VERSION "HIPBNYYYYYYYYYYYYYYYYYYYYYYYYYYYYYYYYYYYYY/4/%%%/4/'%**4YYY///"

NS_ :

BS_:

BU_: ACC AWD SRS EPB GW SAS ESP EMS TCU
VAL_TABLE_ SOC 1023 "Invalid value" 0 "Initial value" ;

BO_ 608 GW_260: 8 GW
 SG_ BCM_ReverseGearPosition : 8|1@0+ (1,0) [0|1] ""  ESP

BO_ 872 ESP_368: 8 ESP
 SG_ ESP_HHC_Active : 15|1@0+ (1,0) [0|1] ""  EPB

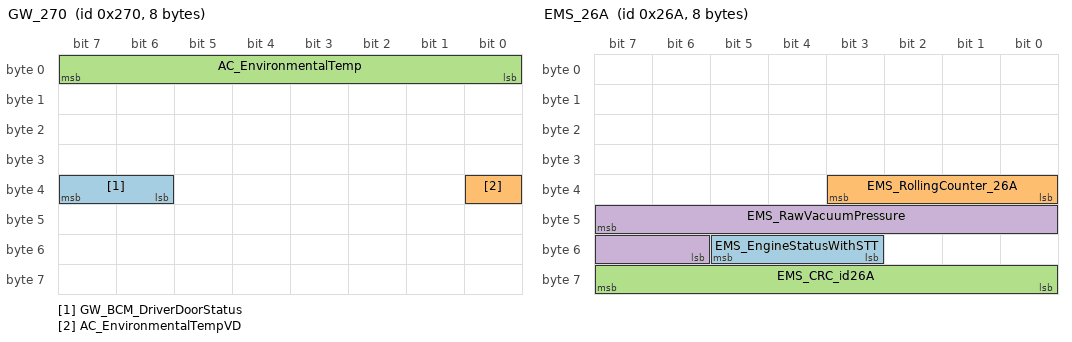
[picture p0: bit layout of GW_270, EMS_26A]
BO_ 624 GW_270: 8 GW
 SG_ GW_BCM_DriverDoorStatus : 39|2@0+ (1,0) [0|3] ""  ESP
 SG_ AC_EnvironmentalTempVD : 32|1@0+ (1,0) [0|1] ""  ESP
 SG_ AC_EnvironmentalTemp : 7|8@0+ (0.5,-40) [-40|87.5] "degree C"  ESP

BO_ 853 EMS_355: 8 EMS
 SG_ EMS_TotalOdometer : 31|24@0+ (1,0) [0|0] ""  ESP

BO_ 618 EMS_26A: 8 EMS
 SG_ EMS_EngineStatusWithSTT : 53|3@0+ (1,0) [0|7] ""  ESP
 SG_ EMS_RollingCounter_26A : 35|4@0+ (1,0) [0|15] ""  ESP
 SG_ EMS_CRC_id26A : 63|8@0+ (1,0) [0|255] ""  ESP
 SG_ EMS_RawVacuumPressure : 47|10@0+ (1.1056,-1080) [-1080|50] "mbar"  ESP

BO_ 631 ESP_277: 8 ESP
 SG_ ESP_TCSActive : 14|1@0+ (1,0) [0|1] ""  ACC
 SG_ ESP_VDCActive : 13|1@0+ (1,0) [0|1] ""  ACC
 SG_ ESP_OnlyABSActive : 15|1@0+ (1,0) [0|1] ""  ACC
 SG_ ESP_BrakeOverHeat : 24|1@0+ (1,0) [0|1] "" Vector__XXX
 SG_ ESP_ABAavailable : 20|1@0+ (1,0) [0|1] "" Vector__XXX
 SG_ ESP_CheckSum_277 : 63|8@0+ (1,0) [0|255] "" Vector__XXX
 SG_ ESP_RollingCounter_277 : 51|4@0+ (1,0) [0|15] "" Vector__XXX
 SG_ ESP_VehicleStandstill : 30|1@0+ (1,0) [0|1] "" Vector__XXX
 SG_ ESP_CDD_Available : 28|1@0+ (1,0) [0|1] "" Vector__XXX
 SG_ ESP_CDD_Active : 27|1@0+ (1,0) [0|1] "" Vector__XXX
 SG_ ESP_QDCACC : 26|2@0+ (1,0) [0|3] "" Vector__XXX
 SG_ ESP_PrefillActive : 23|1@0+ (1,0) [0|1] "" Vector__XXX
 SG_ ESP_PrefillAvailable : 22|1@0+ (1,0) [0|1] "" Vector__XXX
 SG_ ESP_ABAactive : 21|1@0+ (1,0) [0|1] ""  EMS
 SG_ ESP_AEBAvailable : 19|1@0+ (1,0) [0|1] "" Vector__XXX
 SG_ ESP_AEBdecActive : 18|1@0+ (1,0) [0|1] "" Vector__XXX
 SG_ ESP_AWBactive : 17|1@0+ (1,0) [0|1] "" Vector__XXX
 SG_ ESP_AWBavailable : 16|1@0+ (1,0) [0|1] "" Vector__XXX
 SG_ ESP_BrakeForce : 12|1@0+ (1,0) [0|1] "" Vector__XXX

BO_ 862 ACC_35E: 8 ACC
 SG_ ACC_ACCFailInfo : 23|1@0+ (1,0) [0|1] ""  ESP

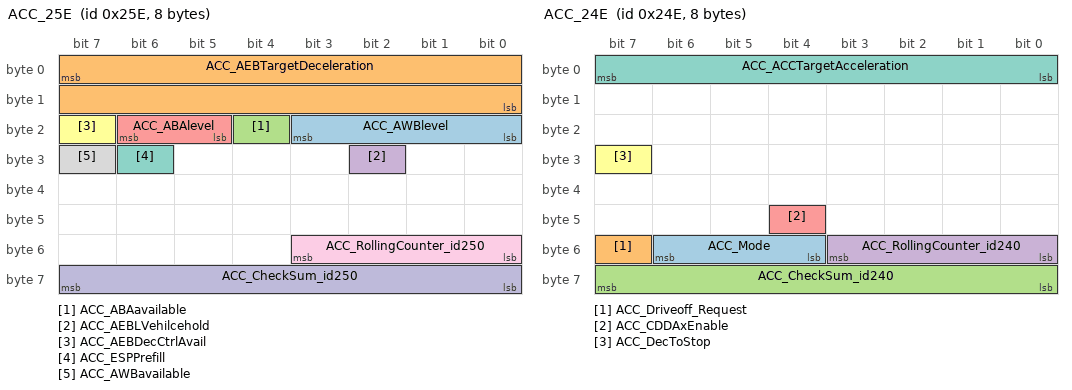
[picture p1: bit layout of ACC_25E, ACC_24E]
BO_ 606 ACC_25E: 8 ACC
 SG_ ACC_AWBlevel : 19|4@0+ (1,0) [0|15] ""  ESP
 SG_ ACC_AEBTargetDeceleration : 7|16@0+ (0.0005,-16) [-16|16] "m/s^2"  ESP
 SG_ ACC_ABAavailable : 20|1@0+ (1,0) [0|1] ""  ESP
 SG_ ACC_AEBLVehilcehold : 26|1@0+ (1,0) [0|1] ""  ESP
 SG_ ACC_ABAlevel : 22|2@0+ (1,0) [0|3] ""  ESP
 SG_ ACC_AEBDecCtrlAvail : 23|1@0+ (1,0) [0|1] ""  ESP
 SG_ ACC_ESPPrefill : 30|1@0+ (1,0) [0|1] ""  ESP
 SG_ ACC_AWBavailable : 31|1@0+ (1,0) [0|1] ""  ESP
 SG_ ACC_RollingCounter_id250 : 51|4@0+ (1,0) [0|15] ""  ESP
 SG_ ACC_CheckSum_id250 : 63|8@0+ (1,0) [0|255] ""  ESP

BO_ 590 ACC_24E: 8 ACC
 SG_ ACC_Mode : 54|3@0+ (1,0) [0|7] "" Vector__XXX
 SG_ ACC_Driveoff_Request : 55|1@0+ (1,0) [0|1] ""  ESP
 SG_ ACC_CheckSum_id240 : 63|8@0+ (1,0) [0|255] ""  ESP
 SG_ ACC_RollingCounter_id240 : 51|4@0+ (1,0) [0|15] ""  ESP
 SG_ ACC_CDDAxEnable : 44|1@0+ (1,0) [0|1] ""  ESP
 SG_ ACC_DecToStop : 31|1@0+ (1,0) [0|1] ""  ESP
 SG_ ACC_ACCTargetAcceleration : 7|8@0+ (0.05,-5) [-5|7.75] "m/s^2"  ESP

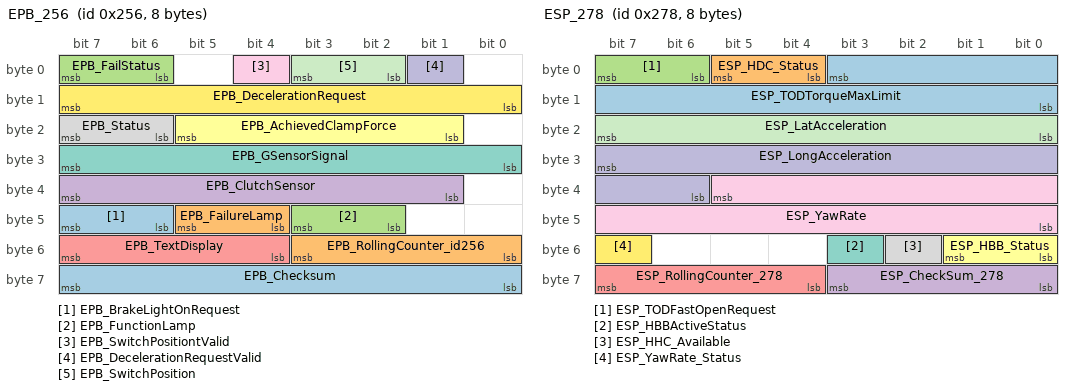
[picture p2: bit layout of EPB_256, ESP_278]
BO_ 598 EPB_256: 8 ESP
 SG_ EPB_BrakeLightOnRequest : 47|2@0+ (1,0) [0|3] ""  EPB
 SG_ EPB_FailureLamp : 45|2@0+ (1,0) [0|3] "" Vector__XXX
 SG_ EPB_FunctionLamp : 43|2@0+ (1,0) [0|3] "" Vector__XXX
 SG_ EPB_ClutchSensor : 39|7@0+ (1,0) [0|127] "" Vector__XXX
 SG_ EPB_TextDisplay : 55|4@0+ (1,0) [0|15] ""  EPB
 SG_ EPB_AchievedClampForce : 21|5@0+ (1,0) [0|31] "KN"  EPB
 SG_ EPB_GSensorSignal : 31|8@0+ (0.1,-12.7) [-12.7|12.7] "m/s^2"  EPB
 SG_ EPB_Status : 23|2@0+ (1,0) [0|3] ""  EPB
 SG_ EPB_SwitchPositiontValid : 4|1@0+ (1,0) [0|1] ""  EPB
 SG_ EPB_DecelerationRequestValid : 1|1@0+ (1,0) [0|1] ""  EPB
 SG_ EPB_SwitchPosition : 3|2@0+ (1,0) [0|3] ""  EPB
 SG_ EPB_DecelerationRequest : 15|8@0+ (0.048,-7.968) [-7.968|4.272] ""  EPB
 SG_ EPB_Checksum : 63|8@0+ (1,0) [0|255] ""  EPB
 SG_ EPB_RollingCounter_id256 : 51|4@0+ (1,0) [0|15] ""  EPB
 SG_ EPB_FailStatus : 7|2@0+ (1,0) [0|3] ""  EPB

BO_ 80 SRS_050: 4 SRS
 SG_ SRS_RollingCounter_id050 : 27|4@0+ (1,0) [0|15] ""  ESP
 SG_ SRS_DriverBuckleSwitchStatus : 15|2@0+ (1,0) [0|3] ""  ESP

BO_ 720 GW_2D0: 8 GW
 SG_ EMS_EngineOffTime : 23|16@0+ (1,0) [0|65535] ""  ESP

BO_ 632 ESP_278: 8 ESP
 SG_ ESP_TODTorqueMaxLimit : 3|12@0+ (1,0) [0|4095] ""  EMS
 SG_ ESP_HDC_Status : 5|2@0+ (1,0) [0|3] ""  EMS
 SG_ ESP_TODFastOpenRequest : 7|2@0+ (1,0) [0|3] ""  EMS
 SG_ ESP_CheckSum_278 : 59|4@0+ (1,0) [0|15] ""  ACC
 SG_ ESP_RollingCounter_278 : 63|4@0+ (1,0) [0|15] ""  EPB
 SG_ ESP_HBB_Status : 49|2@0+ (1,0) [0|3] "" Vector__XXX
 SG_ ESP_HBBActiveStatus : 51|1@0+ (1,0) [0|1] "" Vector__XXX
 SG_ ESP_HHC_Available : 50|1@0+ (1,0) [0|1] "" Vector__XXX
 SG_ ESP_YawRate : 37|14@0+ (0.01,-81.91) [-81.91|81.91] "rad/s"  EMS
 SG_ ESP_LongAcceleration : 31|10@0+ (0.03125,-16) [-16|15.96875] "m/s^2"  EMS
 SG_ ESP_LatAcceleration : 23|8@0+ (0.1,-12.7) [-12.7|12.7] "m/s^2"  EMS
 SG_ ESP_YawRate_Status : 55|1@0+ (1,0) [0|1] ""  EMS

BO_ 568 TCU_238: 8 TCU
 SG_ TCU_ShiftinProgressValid : 4|1@0+ (1,0) [0|1] ""  ESP
 SG_ TCU_ShiftinProgress : 5|1@0+ (1,0) [0|1] ""  ESP

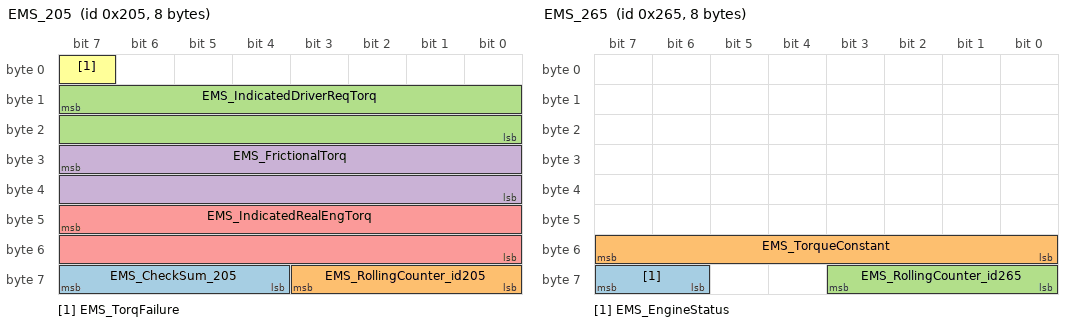
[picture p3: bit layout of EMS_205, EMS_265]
BO_ 517 EMS_205: 8 EMS
 SG_ EMS_CheckSum_205 : 63|4@0+ (1,0) [0|15] "%"  ESP
 SG_ EMS_RollingCounter_id205 : 59|4@0+ (1,0) [0|15] ""  ESP
 SG_ EMS_IndicatedDriverReqTorq : 15|16@0+ (0.001526,0) [0|99.9988] "%"  ESP
 SG_ EMS_FrictionalTorq : 31|16@0+ (0.001526,0) [0|99.9988] "%"  ESP
 SG_ EMS_IndicatedRealEngTorq : 47|16@0+ (0.001526,0) [0|99.9988] "%"  ESP
 SG_ EMS_TorqFailure : 7|1@0+ (1,0) [0|1] ""  ESP

BO_ 613 EMS_265: 8 EMS
 SG_ EMS_EngineStatus : 63|2@0+ (1,0) [0|3] ""  ESP
 SG_ EMS_TorqueConstant : 55|8@0+ (10,0) [0|2540] "Nm"  ESP
 SG_ EMS_RollingCounter_id265 : 59|4@0+ (1,0) [0|15] ""  ESP

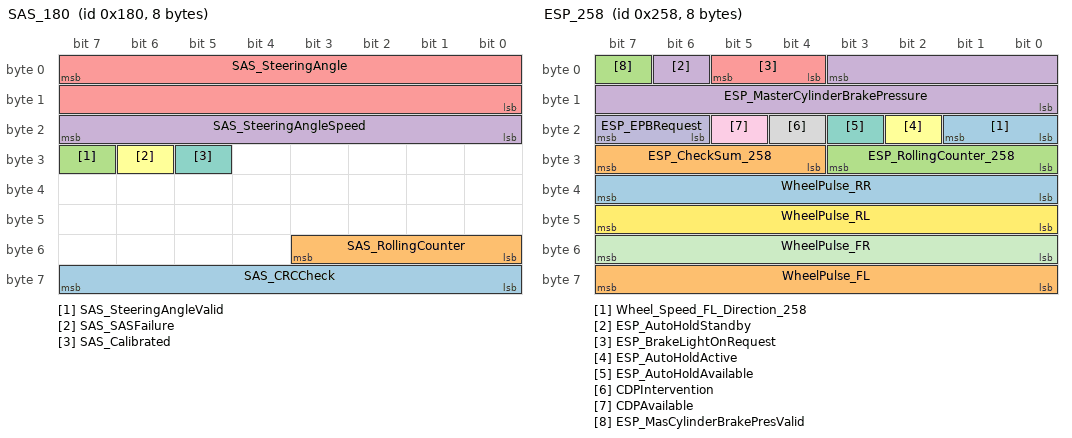
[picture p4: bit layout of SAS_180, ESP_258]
BO_ 384 SAS_180: 8 SAS
 SG_ SAS_CRCCheck : 63|8@0+ (1,0) [0|255] ""  ESP
 SG_ SAS_RollingCounter : 51|4@0+ (1,0) [0|15] ""  ESP
 SG_ SAS_SteeringAngleValid : 31|1@0+ (1,0) [0|1] ""  ESP
 SG_ SAS_SteeringAngleSpeed : 23|8@0+ (4,0) [0|1020] "deg/s"  ESP
 SG_ SAS_SteeringAngle : 7|16@0- (0.1,0) [-780|780] "degree"  ESP
 SG_ SAS_SASFailure : 30|1@0+ (1,0) [0|1] ""  ESP
 SG_ SAS_Calibrated : 29|1@0+ (1,0) [0|1] ""  ESP

BO_ 600 ESP_258: 8 ESP
 SG_ Wheel_Speed_FL_Direction_258 : 17|2@0+ (1,0) [0|3] "" Vector__XXX
 SG_ ESP_CheckSum_258 : 31|4@0+ (1,0) [0|15] "" Vector__XXX
 SG_ ESP_RollingCounter_258 : 27|4@0+ (1,0) [0|15] "" Vector__XXX
 SG_ ESP_AutoHoldStandby : 6|1@0+ (1,0) [0|1] "" Vector__XXX
 SG_ ESP_BrakeLightOnRequest : 5|2@0+ (1,0) [0|3] "" Vector__XXX
 SG_ ESP_AutoHoldActive : 18|1@0+ (1,0) [0|1] "" Vector__XXX
 SG_ ESP_AutoHoldAvailable : 19|1@0+ (1,0) [0|1] "" Vector__XXX
 SG_ CDPIntervention : 20|1@0+ (1,0) [0|1] "" Vector__XXX
 SG_ CDPAvailable : 21|1@0+ (1,0) [0|1] "" Vector__XXX
 SG_ ESP_EPBRequest : 23|2@0+ (1,0) [0|3] ""  EPB
 SG_ WheelPulse_FR : 55|8@0+ (1,0) [0|255] ""  EPB
 SG_ WheelPulse_RL : 47|8@0+ (1,0) [0|255] ""  EPB
 SG_ WheelPulse_RR : 39|8@0+ (1,0) [0|255] ""  EPB
 SG_ WheelPulse_FL : 63|8@0+ (1,0) [0|255] ""  EPB
 SG_ ESP_MasCylinderBrakePresValid : 7|1@0+ (1,0) [0|1] ""  EMS
 SG_ ESP_MasterCylinderBrakePressure : 3|12@0+ (0.1,0) [0|250] "Bar"  EMS

BO_ 536 ESP_218: 8 ESP
 SG_ ESP_ADBFActive : 52|1@0+ (1,0) [0|1] ""  EMS
 SG_ ESP_BrakePedalStatus : 54|2@0+ (1,0) [0|3] ""  EMS
 SG_ ESP_SASFirstRange : 55|1@0+ (1,0) [0|1] "" Vector__XXX
 SG_ ESP_GearHoldRequestValid : 5|1@0+ (1,0) [0|1] ""  EMS
 SG_ ESP_RollingCounter_id218 : 51|4@0+ (1,0) [0|15] "" Vector__XXX
 SG_ ESP_Checksum : 63|8@0+ (1,0) [0|255] "" Vector__XXX
 SG_ ESP_ABSActiveStatus : 7|1@0+ (1,0) [0|1] ""  EMS
 SG_ ESP_GearHoldRequest : 6|1@0+ (1,0) [0|1] ""  EMS
 SG_ ESP_EngTorqDecSlow : 23|8@0+ (0.392,0) [0|99.96] "%"  EMS
 SG_ ESP_ESPSwitchStatus : 1|1@0+ (1,0) [0|1] ""  EMS
 SG_ ESP_ESPFailStatus : 4|1@0+ (1,0) [0|1] ""  TCU
 SG_ ESP_EBDFailStatus : 2|1@0+ (1,0) [0|1] ""  TCU
 SG_ ESP_ABSFailStatus : 3|1@0+ (1,0) [0|1] ""  TCU
 SG_ ESP_VehicleSpeed_Status : 37|1@0+ (1,0) [0|1] ""  EMS
 SG_ ESP_VehicleSpeed : 36|13@0+ (0.05625,0) [0|360] "km/h"  EMS
 SG_ ESP_ESPActiveStatus : 0|1@0+ (1,0) [0|1] ""  TCU
 SG_ ESP_EngTorqInc : 31|8@0+ (0.392,0) [0|99.96] "%" Vector__XXX
 SG_ ESP_EngTorqDecFast : 15|8@0+ (0.392,0) [0|99.96] "%"  EMS
 SG_ ESP_EngTorqDecActive : 39|1@0+ (1,0) [0|1] "" Vector__XXX
 SG_ ESP_EngTorqIncActive : 38|1@0+ (1,0) [0|1] "" Vector__XXX

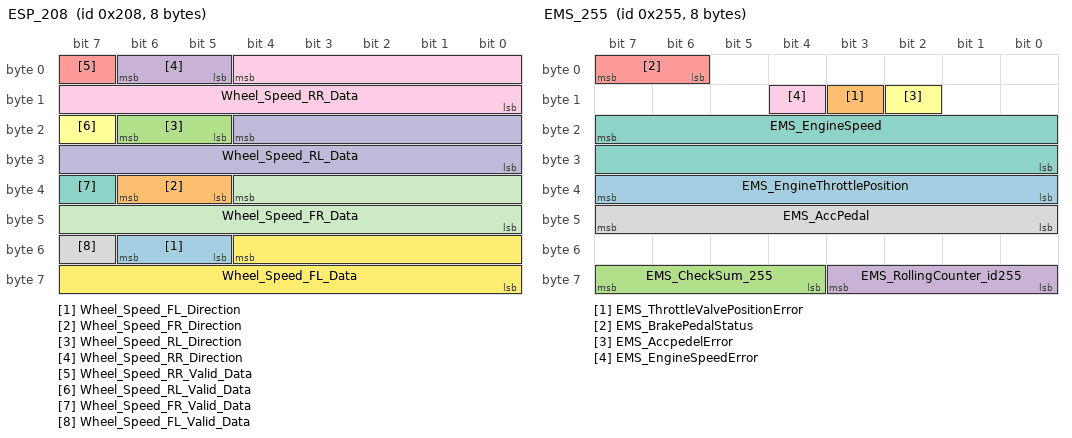
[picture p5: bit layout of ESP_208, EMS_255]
BO_ 520 ESP_208: 8 ESP
 SG_ Wheel_Speed_FL_Direction : 54|2@0+ (1,0) [0|3] ""  EMS
 SG_ Wheel_Speed_FR_Direction : 38|2@0+ (1,0) [0|3] ""  EMS
 SG_ Wheel_Speed_RL_Direction : 22|2@0+ (1,0) [0|3] ""  EMS
 SG_ Wheel_Speed_RR_Direction : 6|2@0+ (1,0) [0|3] ""  EMS
 SG_ Wheel_Speed_RR_Valid_Data : 7|1@0+ (1,0) [0|1] ""  EMS,TCU
 SG_ Wheel_Speed_RL_Valid_Data : 23|1@0+ (1,0) [0|1] ""  EMS,TCU
 SG_ Wheel_Speed_FR_Valid_Data : 39|1@0+ (1,0) [0|1] ""  EMS,TCU
 SG_ Wheel_Speed_FL_Valid_Data : 55|1@0+ (1,0) [0|1] ""  EMS,TCU
 SG_ Wheel_Speed_RR_Data : 4|13@0+ (0.05625,0) [0|360] "Km/h"  EMS,TCU
 SG_ Wheel_Speed_RL_Data : 20|13@0+ (0.05625,0) [0|360] "Km/h"  EMS,TCU
 SG_ Wheel_Speed_FR_Data : 36|13@0+ (0.05625,0) [0|360] "km/h"  EMS,TCU
 SG_ Wheel_Speed_FL_Data : 52|13@0+ (0.05625,0) [0|360] "km/h"  EMS,TCU

BO_ 597 EMS_255: 8 EMS
 SG_ EMS_EngineThrottlePosition : 39|8@0+ (0.392,0) [0|99.568] "%"  ESP
 SG_ EMS_ThrottleValvePositionError : 11|1@0+ (1,0) [0|1] ""  ESP
 SG_ EMS_CheckSum_255 : 63|4@0+ (1,0) [0|15] "%"  ESP
 SG_ EMS_RollingCounter_id255 : 59|4@0+ (1,0) [0|15] ""  ESP
 SG_ EMS_BrakePedalStatus : 7|2@0+ (1,0) [0|3] ""  ESP
 SG_ EMS_AccpedelError : 10|1@0+ (1,0) [0|1] ""  TCU,ESP
 SG_ EMS_EngineSpeed : 23|16@0+ (0.25,0) [0|16383.5] "Rpm"  ESP,TCU
 SG_ EMS_AccPedal : 47|8@0+ (0.392,0) [0|99.568] "%"  ESP,TCU
 SG_ EMS_EngineSpeedError : 12|1@0+ (1,0) [0|1] ""  TCU,ESP

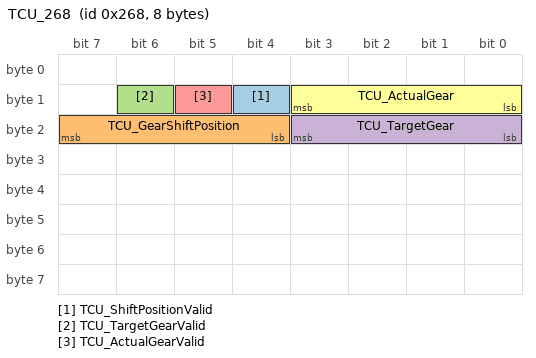
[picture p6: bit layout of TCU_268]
BO_ 616 TCU_268: 8 TCU
 SG_ TCU_ShiftPositionValid : 12|1@0+ (1,0) [0|1] ""  ESP
 SG_ TCU_GearShiftPosition : 23|4@0+ (1,0) [0|15] ""  ESP
 SG_ TCU_TargetGearValid : 14|1@0+ (1,0) [0|1] ""  ESP
 SG_ TCU_TargetGear : 19|4@0+ (1,0) [0|15] ""  ESP
 SG_ TCU_ActualGearValid : 13|1@0+ (1,0) [0|1] ""  ESP,EMS
 SG_ TCU_ActualGear : 11|4@0+ (1,0) [0|15] ""  ESP,EMS

CM_ SG_ 568 TCU_ShiftinProgressValid "1: invalid
0: valid";
CM_ SG_ 384 SAS_SASFailure "0x0£ºNo Failure£»
0x1£ºFailure";
CM_ SG_ 384 SAS_Calibrated "0x0£ºCalibrated£» 
0x1£ºNot Calibrated";
CM_ SG_ 600 ESP_MasCylinderBrakePresValid "0:Valid 
1:Invalid";
CM_ SG_ 536 ESP_GearHoldRequest "0: shifting not
suppressed
1: shifting
suppressed";
CM_ SG_ 536 ESP_ESPSwitchStatus "0: Off
1: On";
CM_ SG_ 536 ESP_ESPFailStatus "0:Normal                          
1:Fault";
CM_ SG_ 536 ESP_EBDFailStatus "0:Normal                                 
1:Fault";
CM_ SG_ 536 ESP_ABSFailStatus "0:Normal                                 
1:Fault";
CM_ SG_ 536 ESP_VehicleSpeed_Status "1: invalid
0: valid";
CM_ SG_ 536 ESP_ESPActiveStatus "0: inactive
1: active";
CM_ SG_ 536 ESP_EngTorqDecActive "0: inactive
1: active";
CM_ SG_ 536 ESP_EngTorqIncActive "0: inactive
1: active";
CM_ SG_ 520 Wheel_Speed_RR_Valid_Data "1: invalid
0: valid";
CM_ SG_ 520 Wheel_Speed_FR_Valid_Data "1: invalid
0: valid";
CM_ SG_ 597 EMS_ThrottleValvePositionError "0x0£ºNo error£» 0x1£ºError, ";
CM_ SG_ 597 EMS_AccpedelError "0x0£ºNo error£» 0x1£ºError, ";
CM_ SG_ 597 EMS_EngineSpeedError "0x0£ºNo error£» 0x1£ºError, ";
CM_ SG_ 616 TCU_ShiftPositionValid "1: invalid
0: valid";
CM_ SG_ 616 TCU_TargetGearValid "1: invalid
0: valid";
CM_ SG_ 616 TCU_ActualGearValid "1: invalid
0: valid";
BA_DEF_ BO_  "GenMsgILSupport" ENUM  "No","Yes";
BA_DEF_ BO_  "ILUsed" ENUM  "No","Yes";
BA_DEF_ BO_  "GenMsgSendType" ENUM  "cyclic","spontaneous","cyclicIfActive","spontaneousWithDelay","cyclicAndSpontaneous","cyclicAndSpontaneousWithDelay","spontaneousWithRepetition","cyclicIfActiveAndSpontaneousWD";
BA_DEF_ BO_  "GenMsgDelayTime" INT 1 1000;
BA_DEF_ BO_  "GenMsgCycleTime" INT 2 50000;
BA_DEF_ SG_  "GenSigStartValue" FLOAT 0 100000000000;
BA_DEF_  "BusType" STRING ;
BA_DEF_ BU_  "NodeLayerModules" STRING ;
BA_DEF_DEF_  "GenMsgILSupport" "Yes";
BA_DEF_DEF_  "ILUsed" "Yes";
BA_DEF_DEF_  "GenMsgSendType" "cyclic";
BA_DEF_DEF_  "GenMsgDelayTime" 1;
BA_DEF_DEF_  "GenMsgCycleTime" 100;
BA_DEF_DEF_  "GenSigStartValue" 0;
BA_DEF_DEF_  "BusType" "";
BA_DEF_DEF_  "NodeLayerModules" "CANoeILNLVector.dll";
BA_ "BusType" "CAN";
BA_ "GenMsgCycleTime" BO_ 608 40;
BA_ "GenMsgCycleTime" BO_ 624 40;
BA_ "GenMsgCycleTime" BO_ 618 20;
BA_ "GenMsgCycleTime" BO_ 631 20;
BA_ "GenMsgCycleTime" BO_ 606 20;
BA_ "GenMsgCycleTime" BO_ 590 20;
BA_ "GenMsgCycleTime" BO_ 598 10;
BA_ "GenMsgCycleTime" BO_ 80 500;
BA_ "GenMsgCycleTime" BO_ 632 20;
BA_ "GenMsgCycleTime" BO_ 568 10;
BA_ "GenMsgCycleTime" BO_ 517 10;
BA_ "GenMsgCycleTime" BO_ 613 10;
BA_ "GenMsgCycleTime" BO_ 384 10;
BA_ "GenMsgCycleTime" BO_ 600 20;
BA_ "GenMsgCycleTime" BO_ 536 10;
BA_ "GenMsgCycleTime" BO_ 520 20;
BA_ "GenMsgCycleTime" BO_ 597 10;
BA_ "GenMsgCycleTime" BO_ 616 10;
BA_ "GenSigStartValue" SG_ 624 AC_EnvironmentalTemp 255;
BA_ "GenSigStartValue" SG_ 618 EMS_RawVacuumPressure 976.84515195369;
BA_ "GenSigStartValue" SG_ 631 ESP_ABAavailable 1;
BA_ "GenSigStartValue" SG_ 631 ESP_PrefillAvailable 1;
BA_ "GenSigStartValue" SG_ 631 ESP_ABAactive 1;
BA_ "GenSigStartValue" SG_ 631 ESP_AEBAvailable 1;
BA_ "GenSigStartValue" SG_ 631 ESP_AEBdecActive 1;
BA_ "GenSigStartValue" SG_ 631 ESP_AWBactive 1;
BA_ "GenSigStartValue" SG_ 631 ESP_AWBavailable 1;
BA_ "GenSigStartValue" SG_ 631 ESP_BrakeForce 1;
BA_ "GenSigStartValue" SG_ 606 ACC_AEBTargetDeceleration 32000;
BA_ "GenSigStartValue" SG_ 590 ACC_ACCTargetAcceleration 100;
BA_ "GenSigStartValue" SG_ 598 EPB_GSensorSignal 127;
BA_ "GenSigStartValue" SG_ 598 EPB_DecelerationRequest 166;
BA_ "GenSigStartValue" SG_ 632 ESP_YawRate 8191;
BA_ "GenSigStartValue" SG_ 632 ESP_LongAcceleration 512;
BA_ "GenSigStartValue" SG_ 632 ESP_LatAcceleration 127;
BA_ "GenSigStartValue" SG_ 536 ESP_BrakePedalStatus 1;
BA_ "GenSigStartValue" SG_ 536 ESP_EngTorqDecSlow 254;
BA_ "GenSigStartValue" SG_ 536 ESP_ESPFailStatus 1;
BA_ "GenSigStartValue" SG_ 536 ESP_EBDFailStatus 1;
BA_ "GenSigStartValue" SG_ 536 ESP_ABSFailStatus 1;
BA_ "GenSigStartValue" SG_ 536 ESP_EngTorqDecFast 254;
